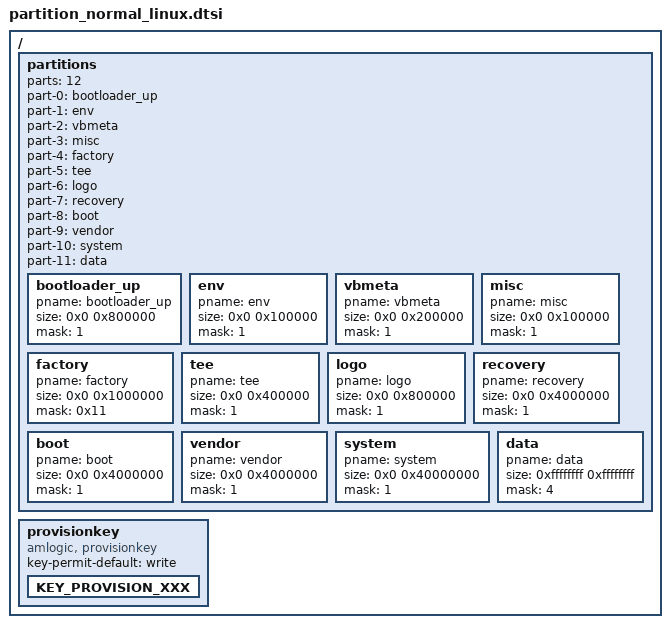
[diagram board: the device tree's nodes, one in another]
// SPDX-License-Identifier: (GPL-2.0+ OR MIT)
/*
 * Amlogic partition set for normal
 *
 * Copyright (c) 2017-2017 Amlogic Ltd
 *
 * This file is licensed under a dual GPLv2 or BSD license.
 *
 */

/ {
		/* will be overlay by emmc_partition_overlay.dtsi */
    partitions: partitions{
		parts = <12>;
		part-0 = <&bootloader_up>;
		part-1 = <&env>;
		part-2 = <&vbmeta>;
		part-3 = <&misc>;
		part-4 = <&factory>;
		part-5 = <&tee>;
		part-6 = <&logo>;
		part-7 = <&recovery>;
		part-8 = <&boot>;
		part-9 = <&vendor>;
		part-10 = <&system>;
		part-11 = <&data>;

		bootloader_up:bootloader_up{
			pname = "bootloader_up";
			size = <0x0 0x800000>;
			mask = <1>;
		};
		env:env{
			pname = "env";
			size = <0x0 0x100000>;
			mask = <1>;
		};
		vbmeta:vbmeta{
			pname = "vbmeta";
			size = <0x0 0x200000>;
			mask = <1>;
		};
		misc:misc{
			pname = "misc";
			size = <0x0 0x100000>;
			mask = <1>;
		};
		factory:factory{
			pname = "factory";
			size = <0x0 0x1000000>;
			mask = <0x11>;
		};
		tee:tee{
			pname = "tee";
			size = <0x0 0x400000>;
			mask = <1>;
		};
		logo:logo{
			pname = "logo";
			size = <0x0 0x800000>;
			mask = <1>;
		};
		recovery:recovery{
			pname = "recovery";
			size = <0x0 0x4000000>;
			mask = <1>;
		};
		boot:boot{
			pname = "boot";
			size = <0x0 0x4000000>;
			mask = <1>;
		};
		vendor:vendor{
			pname = "vendor";
			size = <0x0 0x4000000>;
			mask = <1>;
		};
		system:system{
			pname = "system";
			size = <0x0 0x40000000>;
			mask = <1>;
		};
		data:data{
			pname = "data";
			size = <0xffffffff 0xffffffff>;
			mask = <4>;
		};
	};

	provisionkey {
		compatible = "amlogic, provisionkey";
		status = "okay";
		key-permit-default = "write";
		//new key not need add dts if started with KEY_PROVISION_
		KEY_PROVISION_XXX { };
		//test_my_added_keyname { };
	};//End provisionkey

};/* end of / */
